# V32F20x_CM33 register map
File version: 1.0.3
CPU: CM33 r0p4, little endian, MPU, FPU, DSP, 3 interrupt priority bits, 8 SAU regions
Registers are 32-bit, read-write, reset 0x0 unless marked. A register's access mark holds for its fields unless they carry their own. Offsets are from the block's base; [hi:lo] are bit positions.

## RTCALM — RTCALM Peripheral Interface
Base 0x40102800
Same registers: SEC_RTCALM 0x50102800
0x00 WKUSEC — Multi-second low-power wakeup or interrupt register
  [5:0] WKUSEC — Control the multi second wakeup function in low power mode
0x04 WKUMIN — Multi-minute low-power wakeup or interrupt register
  [5:0] WKUMIN — Control the multi minute wakeup function in low power mode
0x08 WKUHOUR — Multi-hour low-power wakeup or interrupt register.
  [4:0] WKUHOUR — Control the multi hour wakeup function in low power mode
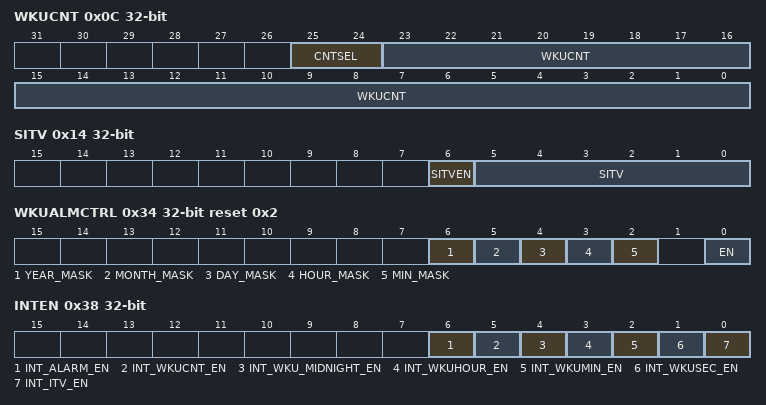
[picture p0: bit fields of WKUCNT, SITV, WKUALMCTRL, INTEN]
0x0C WKUCNT — Clock counter low-power wakeup or interrupt register
  [25:24] CNTSEL — Select the counter clock .
  [23:0] WKUCNT — Count of counter clocks
0x10 ITV — Multi-interval low-power wakeup or interrupt control register
  [2:0] ITV — Control multi interval wakeup and interrupt
0x14 SITV — Multi-second-interval low-power wakeup or interrupt control register
  [6] SITVEN — Multi second interval enable and valid only when ITV is set to 7
  [5:0] SITV — Count of seconds valid only when ITV is 7 and SITVEN is 1
0x1C ALARMSEC — Inaccurate second alarm control register.
  [6:0] SEC — RTC alarm time second in BCD format.
0x20 ALARMMIN — Minute alarm control register.
  [6:0] MIN — RTC alarm time minute in BCD format.
0x24 ALARMHOUR — Hour alarm control register.
  [5:0] HOUR — RTC alarm time hour in BCD format.
0x28 ALARMDAY — Day alarm control register.
  [5:0] DAY — RTC alarm time day in BCD format.
0x2C ALARMMONTH — Month alarm control register.
  [4:0] MONTH — RTC alarm time month in BCD format..
0x30 ALARMYEAR — Year alarm control register.
  [7:0] YEAR — RTC alarm time year in BCD format..
0x34 WKUALMCTRL reset 0x2 — Alarm and wakeup control register.
  [6] YEAR_MASK — Alarm time year mask
  [5] MONTH_MASK — Alarm time month mask
  [4] DAY_MASK — Alarm time day mask
  [3] HOUR_MASK — Alarm time hour mask
  [2] MIN_MASK — Alarm time minute mask
  [0] EN — Alarm function enable
0x38 INTEN — Interrupt enable register.
  [6] INT_ALARM_EN — Alarm interrupt enable.
  [5] INT_WKUCNT_EN — Clock counter wakeup interrupt enable.
  [4] INT_WKU_MIDNIGHT_EN — Midnight wakeup interrupt enable.
  [3] INT_WKUHOUR_EN — Multi-hour wakeup interrupt enable.
  [2] INT_WKUMIN_EN — Multi-minute wakeup interrupt enable.
  [1] INT_WKUSEC_EN — Multi-second wakeup interrupt enable.
  [0] INT_ITV_EN — Multi interval and multi second interval wakeup interrupt enable
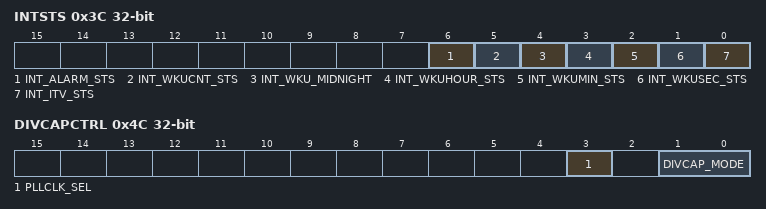
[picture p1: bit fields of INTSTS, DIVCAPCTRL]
0x3C INTSTS — Interrupt status register.
  [6] INT_ALARM_STS — Alarm interrupt status.
  [5] INT_WKUCNT_STS — Clock counter wakeup interrupt status.
  [4] INT_WKU_MIDNIGHT — Midnight wakeup interrupt status.
  [3] INT_WKUHOUR_STS — Multi-hour wakeup interrupt status.
  [2] INT_WKUMIN_STS — Multi-minute wakeup interrupt status.
  [1] INT_WKUSEC_STS — Multi-second wakeup interrupt status.
  [0] INT_ITV_STS — Multi interval and Multi interval and multi second interval wakeup interrupt status
0x40 WKUCNTR — current WKUCNT value register.
  [23:0] WKUCNTR — Current WKUCNT value.
0x44 CFGVALID — Configuration done flag register.
  [0] CFG_VALID — Configuration information really valid.
0x48 STS — Configuration status register.
  [0] CFG_BUSY — Configuration busy flag.
0x4C DIVCAPCTRL — High-frequency clock divide and second pulse capture control register
  [3] PLLCLK_SEL — Select the source of rtc pll divide clock
  [1:0] DIVCAP_MODE — This field is used to control the divide capture mode
0x50 PLLDIV — PLL divider register.
  [25:0] PLLDIV — This field has three fuctions the first function is storing PLL divider value in capture mode the second function is storing value of RTC_PLLDIVAC register and the last is also used as clock divider in high frequency divide mode
